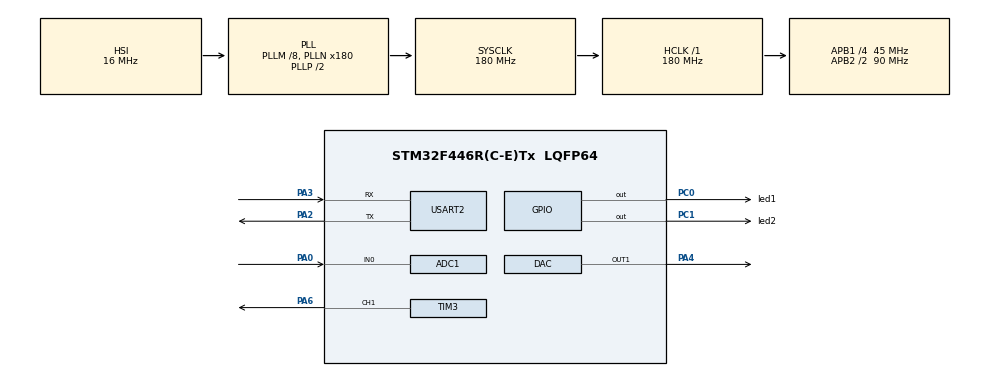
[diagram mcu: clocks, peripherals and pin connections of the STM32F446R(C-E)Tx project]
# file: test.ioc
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ADC1.Channel-0\#ChannelRegularConversion=ADC_CHANNEL_0
ADC1.NbrOfConversionFlag=1
ADC1.Rank-0\#ChannelRegularConversion=1
ADC1.SamplingTime-0\#ChannelRegularConversion=ADC_SAMPLETIME_3CYCLES
ADC1.master=1
Mcu.Family=STM32F4
Mcu.Name=STM32F446R(C-E)Tx
Mcu.Package=LQFP64
NVIC.PriorityGroup=NVIC_PRIORITYGROUP_4
PA0-WKUP.Signal=ADCx_IN0
PA2.Mode=Asynchronous
PA2.Signal=USART2_TX
PA3.Mode=Asynchronous
PA3.Signal=USART2_RX
PA4.Signal=COMP_DAC1_group
PA6.Signal=S_TIM3_CH1
PC0.GPIO_Label=led1
PC0.GPIO_ModeDefaultOutputPP=GPIO_MODE_OUTPUT_PP
PC0.GPIO_PuPd=GPIO_NOPULL
PC0.GPIO_Speed=GPIO_SPEED_FREQ_MEDIUM
PC0.PinState=GPIO_PIN_RESET
PC0.Signal=GPIO_Output
PC1.GPIO_Label=led2
PC1.GPIO_ModeDefaultOutputPP=GPIO_MODE_OUTPUT_PP
PC1.GPIO_PuPd=GPIO_NOPULL
PC1.GPIO_Speed=GPIO_SPEED_FREQ_MEDIUM
PC1.PinState=GPIO_PIN_RESET
PC1.Signal=GPIO_Output
ProjectManager.HeapSize=0x200
ProjectManager.StackSize=0x400
ProjectManager.TargetToolchain=STM32CubeIDE
RCC.AHBFreq_Value=180000000
RCC.APB1CLKDivider=RCC_HCLK_DIV4
RCC.APB1Freq_Value=45000000
RCC.APB1TimFreq_Value=90000000
RCC.APB2CLKDivider=RCC_HCLK_DIV2
RCC.APB2Freq_Value=90000000
RCC.APB2TimFreq_Value=180000000
RCC.CortexFreq_Value=180000000
RCC.HCLKFreq_Value=180000000
RCC.PLLM=8
RCC.PLLN=180
RCC.SYSCLKFreq_VALUE=180000000
RCC.SYSCLKSource=RCC_SYSCLKSOURCE_PLLCLK
RCC.USBFreq_Value=180000000
RCC.VCOOutputFreq_Value=360000000
SH.ADCx_IN0.0=ADC1_IN0,IN0
SH.COMP_DAC1_group.0=DAC_OUT1,DAC_OUT1
SH.S_TIM3_CH1.0=TIM3_CH1,PWM Generation1 CH1
TIM3.Channel-PWM\ Generation1\ CH1=TIM_CHANNEL_1
TIM3.Period=4500-1
TIM3.Prescaler=90-1
USART2.VirtualMode=VM_ASYNC
board=custom

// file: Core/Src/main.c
/* USER CODE BEGIN Header */
/**
  ******************************************************************************
  * @file           : main.c
  * @brief          : Main program body
  ******************************************************************************
  * @attention
  *
  * Copyright (c) 2025 STMicroelectronics.
  * All rights reserved.
  *
  * This software is licensed under terms that can be found in the LICENSE file
  * in the root directory of this software component.
  * If no LICENSE file comes with this software, it is provided AS-IS.
  *
  ******************************************************************************
  */
/* USER CODE END Header */
#include "main.h"

/* USER CODE BEGIN Includes */
#include "stdio.h"
/* USER CODE END Includes */

ADC_HandleTypeDef hadc1;

DAC_HandleTypeDef hdac;

TIM_HandleTypeDef htim3;

UART_HandleTypeDef huart2;

void SystemClock_Config(void);
static void MX_GPIO_Init(void);
static void MX_ADC1_Init(void);
static void MX_DAC_Init(void);
static void MX_USART2_UART_Init(void);
static void MX_TIM3_Init(void);

/* USER CODE BEGIN 0 */
ADC_HandleTypeDef hadc1;
DAC_HandleTypeDef hdac;
UART_HandleTypeDef huart2;

uint32_t adc_val = 0;
char msg[64];

/* USER CODE END 0 */

int main(void)
{

  /* MCU Configuration--------------------------------------------------------*/

  /* Reset of all peripherals, Initializes the Flash interface and the Systick. */
  HAL_Init();

  /* Configure the system clock */
  SystemClock_Config();

  /* Initialize all configured peripherals */
  MX_GPIO_Init();
  MX_ADC1_Init();
  MX_DAC_Init();
  MX_USART2_UART_Init();
  MX_TIM3_Init();
  /* USER CODE BEGIN 2 */
  HAL_DAC_Start(&hdac, DAC_CHANNEL_1);
  HAL_TIM_PWM_Start(&htim3, TIM_CHANNEL_1);
  /* USER CODE END 2 */

  /* Infinite loop */
  /* USER CODE BEGIN WHILE */
  while (1)
  {
	  HAL_GPIO_WritePin(led2_GPIO_Port, led2_Pin, SET);
	  HAL_GPIO_WritePin(led1_GPIO_Port, led1_Pin, RESET);
	  for(int i =0; i< 4499; i +=10){
		  __HAL_TIM_SET_COMPARE(&htim3, TIM_CHANNEL_1, i);

		  HAL_Delay(20);
	  }

    /* USER CODE END WHILE */

  }
}

void SystemClock_Config(void)
{
  RCC_OscInitTypeDef RCC_OscInitStruct = {0};
  RCC_ClkInitTypeDef RCC_ClkInitStruct = {0};

  /** Configure the main internal regulator output voltage
  */
  __HAL_RCC_PWR_CLK_ENABLE();
  __HAL_PWR_VOLTAGESCALING_CONFIG(PWR_REGULATOR_VOLTAGE_SCALE1);

  /** Initializes the RCC Oscillators according to the specified parameters
  * in the RCC_OscInitTypeDef structure.
  */
  RCC_OscInitStruct.OscillatorType = RCC_OSCILLATORTYPE_HSI;
  RCC_OscInitStruct.HSIState = RCC_HSI_ON;
  RCC_OscInitStruct.HSICalibrationValue = RCC_HSICALIBRATION_DEFAULT;
  RCC_OscInitStruct.PLL.PLLState = RCC_PLL_ON;
  RCC_OscInitStruct.PLL.PLLSource = RCC_PLLSOURCE_HSI;
  RCC_OscInitStruct.PLL.PLLM = 8;
  RCC_OscInitStruct.PLL.PLLN = 180;
  RCC_OscInitStruct.PLL.PLLP = RCC_PLLP_DIV2;
  RCC_OscInitStruct.PLL.PLLQ = 2;
  RCC_OscInitStruct.PLL.PLLR = 2;
  if (HAL_RCC_OscConfig(&RCC_OscInitStruct) != HAL_OK)
  {
    Error_Handler();
  }

  /** Activate the Over-Drive mode
  */
  if (HAL_PWREx_EnableOverDrive() != HAL_OK)
  {
    Error_Handler();
  }

  /** Initializes the CPU, AHB and APB buses clocks
  */
  RCC_ClkInitStruct.ClockType = RCC_CLOCKTYPE_HCLK|RCC_CLOCKTYPE_SYSCLK
                              |RCC_CLOCKTYPE_PCLK1|RCC_CLOCKTYPE_PCLK2;
  RCC_ClkInitStruct.SYSCLKSource = RCC_SYSCLKSOURCE_PLLCLK;
  RCC_ClkInitStruct.AHBCLKDivider = RCC_SYSCLK_DIV1;
  RCC_ClkInitStruct.APB1CLKDivider = RCC_HCLK_DIV4;
  RCC_ClkInitStruct.APB2CLKDivider = RCC_HCLK_DIV2;

  if (HAL_RCC_ClockConfig(&RCC_ClkInitStruct, FLASH_LATENCY_5) != HAL_OK)
  {
    Error_Handler();
  }
}

static void MX_ADC1_Init(void)
{

  ADC_ChannelConfTypeDef sConfig = {0};

  /** Configure the global features of the ADC (Clock, Resolution, Data Alignment and number of conversion)
  */
  hadc1.Instance = ADC1;
  hadc1.Init.ClockPrescaler = ADC_CLOCK_SYNC_PCLK_DIV4;
  hadc1.Init.Resolution = ADC_RESOLUTION_12B;
  hadc1.Init.ScanConvMode = DISABLE;
  hadc1.Init.ContinuousConvMode = DISABLE;
  hadc1.Init.DiscontinuousConvMode = DISABLE;
  hadc1.Init.ExternalTrigConvEdge = ADC_EXTERNALTRIGCONVEDGE_NONE;
  hadc1.Init.ExternalTrigConv = ADC_SOFTWARE_START;
  hadc1.Init.DataAlign = ADC_DATAALIGN_RIGHT;
  hadc1.Init.NbrOfConversion = 1;
  hadc1.Init.DMAContinuousRequests = DISABLE;
  hadc1.Init.EOCSelection = ADC_EOC_SINGLE_CONV;
  if (HAL_ADC_Init(&hadc1) != HAL_OK)
  {
    Error_Handler();
  }

  /** Configure for the selected ADC regular channel its corresponding rank in the sequencer and its sample time.
  */
  sConfig.Channel = ADC_CHANNEL_0;
  sConfig.Rank = 1;
  sConfig.SamplingTime = ADC_SAMPLETIME_3CYCLES;
  if (HAL_ADC_ConfigChannel(&hadc1, &sConfig) != HAL_OK)
  {
    Error_Handler();
  }

}

static void MX_DAC_Init(void)
{

  DAC_ChannelConfTypeDef sConfig = {0};

  /** DAC Initialization
  */
  hdac.Instance = DAC;
  if (HAL_DAC_Init(&hdac) != HAL_OK)
  {
    Error_Handler();
  }

  /** DAC channel OUT1 config
  */
  sConfig.DAC_Trigger = DAC_TRIGGER_NONE;
  sConfig.DAC_OutputBuffer = DAC_OUTPUTBUFFER_ENABLE;
  if (HAL_DAC_ConfigChannel(&hdac, &sConfig, DAC_CHANNEL_1) != HAL_OK)
  {
    Error_Handler();
  }

}

static void MX_TIM3_Init(void)
{

  TIM_MasterConfigTypeDef sMasterConfig = {0};
  TIM_OC_InitTypeDef sConfigOC = {0};

  htim3.Instance = TIM3;
  htim3.Init.Prescaler = 90-1;
  htim3.Init.CounterMode = TIM_COUNTERMODE_UP;
  htim3.Init.Period = 4500-1;
  htim3.Init.ClockDivision = TIM_CLOCKDIVISION_DIV1;
  htim3.Init.AutoReloadPreload = TIM_AUTORELOAD_PRELOAD_DISABLE;
  if (HAL_TIM_PWM_Init(&htim3) != HAL_OK)
  {
    Error_Handler();
  }
  sMasterConfig.MasterOutputTrigger = TIM_TRGO_RESET;
  sMasterConfig.MasterSlaveMode = TIM_MASTERSLAVEMODE_DISABLE;
  if (HAL_TIMEx_MasterConfigSynchronization(&htim3, &sMasterConfig) != HAL_OK)
  {
    Error_Handler();
  }
  sConfigOC.OCMode = TIM_OCMODE_PWM1;
  sConfigOC.Pulse = 0;
  sConfigOC.OCPolarity = TIM_OCPOLARITY_HIGH;
  sConfigOC.OCFastMode = TIM_OCFAST_DISABLE;
  if (HAL_TIM_PWM_ConfigChannel(&htim3, &sConfigOC, TIM_CHANNEL_1) != HAL_OK)
  {
    Error_Handler();
  }
  HAL_TIM_MspPostInit(&htim3);

}

static void MX_USART2_UART_Init(void)
{

  huart2.Instance = USART2;
  huart2.Init.BaudRate = 115200;
  huart2.Init.WordLength = UART_WORDLENGTH_8B;
  huart2.Init.StopBits = UART_STOPBITS_1;
  huart2.Init.Parity = UART_PARITY_NONE;
  huart2.Init.Mode = UART_MODE_TX_RX;
  huart2.Init.HwFlowCtl = UART_HWCONTROL_NONE;
  huart2.Init.OverSampling = UART_OVERSAMPLING_16;
  if (HAL_UART_Init(&huart2) != HAL_OK)
  {
    Error_Handler();
  }

}

static void MX_GPIO_Init(void)
{
  GPIO_InitTypeDef GPIO_InitStruct = {0};

  /* GPIO Ports Clock Enable */
  __HAL_RCC_GPIOC_CLK_ENABLE();
  __HAL_RCC_GPIOA_CLK_ENABLE();

  /*Configure GPIO pin Output Level */
  HAL_GPIO_WritePin(GPIOC, led1_Pin|led2_Pin, GPIO_PIN_RESET);

  /*Configure GPIO pins : led1_Pin led2_Pin */
  GPIO_InitStruct.Pin = led1_Pin|led2_Pin;
  GPIO_InitStruct.Mode = GPIO_MODE_OUTPUT_PP;
  GPIO_InitStruct.Pull = GPIO_NOPULL;
  GPIO_InitStruct.Speed = GPIO_SPEED_FREQ_MEDIUM;
  HAL_GPIO_Init(GPIOC, &GPIO_InitStruct);

}

void Error_Handler(void)
{
  __disable_irq();
  while (1)
  {
  }
}
